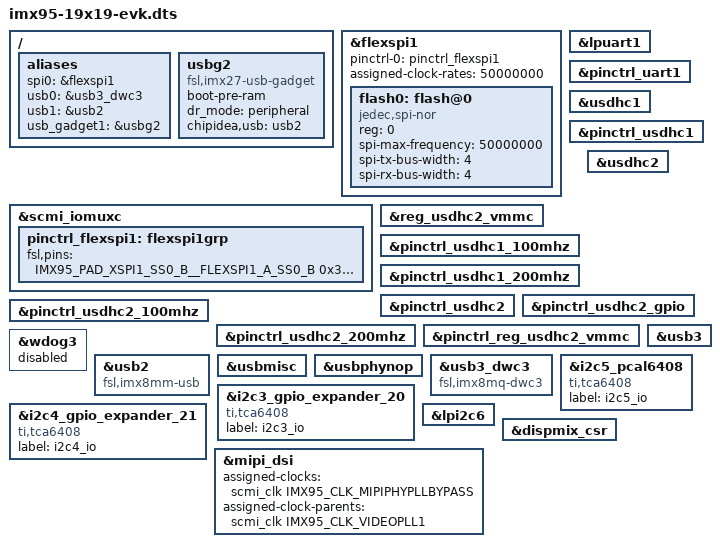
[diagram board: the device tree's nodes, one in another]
// SPDX-License-Identifier: (GPL-2.0+ OR MIT)
/*
 * Copyright 2023-2024 NXP
 */

#include "../dts/upstream/src/arm64/freescale/imx95-19x19-evk.dts"
#include "imx95-u-boot.dtsi"
#include "imx95-19x19-evk-local.dtsi"

&flexspi1 {
	/delete-node/ flash@0;
};

/delete-node/ &pinctrl_flexspi1;
/delete-node/ &pinctrl_flexspi1_reset;

/ {
	aliases {
		spi0 = &flexspi1;
		usb0 = &usb3_dwc3;
		usb1 = &usb2;
		usb_gadget1 = &usbg2;
	};

	usbg2: usbg2 {
		boot-pre-ram;
		compatible = "fsl,imx27-usb-gadget";
		dr_mode = "peripheral";
		chipidea,usb = <&usb2>;
		status = "okay";
	};
};

&flexspi1 {
	bootph-pre-ram;
	pinctrl-names = "default";
	pinctrl-0 = <&pinctrl_flexspi1>;
	assigned-clock-rates = <50000000>; // 50 MHz
	status = "okay";

	flash0: flash@0 {
		bootph-pre-ram;
		compatible = "jedec,spi-nor";
		reg = <0>;
		#address-cells = <1>;
		#size-cells = <1>;
		spi-max-frequency = <50000000>; // 50 MHz
		spi-tx-bus-width = <4>;
		spi-rx-bus-width = <4>;
	};
};

&scmi_iomuxc {
	pinctrl-names = "default";

	pinctrl_flexspi1: flexspi1grp {
		bootph-pre-ram;
		fsl,pins = <
			IMX95_PAD_XSPI1_SS0_B__FLEXSPI1_A_SS0_B		0x3fe
			IMX95_PAD_XSPI1_SCLK__FLEXSPI1_A_SCLK		0x3fe
			IMX95_PAD_XSPI1_DATA0__FLEXSPI1_A_DATA_BIT0	0x3fe
			IMX95_PAD_XSPI1_DATA1__FLEXSPI1_A_DATA_BIT1	0x3fe
			IMX95_PAD_XSPI1_DATA2__FLEXSPI1_A_DATA_BIT2	0x3fe
			IMX95_PAD_XSPI1_DATA3__FLEXSPI1_A_DATA_BIT3	0x3fe
		>;
	};
};

&lpuart1 {
	bootph-pre-ram;
};

&pinctrl_uart1 {
	bootph-pre-ram;
};

&reg_usdhc2_vmmc {
	bootph-pre-ram;
};

&usdhc1 {
	bootph-pre-ram;
};

&pinctrl_usdhc1 {
	bootph-pre-ram;
};

&pinctrl_usdhc1_100mhz {
	bootph-pre-ram;
};

&pinctrl_usdhc1_200mhz {
	bootph-pre-ram;
};

&usdhc2 {
	bootph-pre-ram;
};

&pinctrl_usdhc2 {
	bootph-pre-ram;
};

&pinctrl_usdhc2_100mhz {
	bootph-pre-ram;
};

&pinctrl_usdhc2_200mhz {
	bootph-pre-ram;
};

&pinctrl_usdhc2_gpio {
	bootph-pre-ram;
};

&pinctrl_reg_usdhc2_vmmc {
	bootph-pre-ram;
};

&wdog3 {
	status = "disabled";
};

&usb2 {
	bootph-pre-ram;
	compatible = "fsl,imx8mm-usb", "fsl,imx7d-usb";
	/delete-property/ power-domains;
};

&usbmisc {
	bootph-pre-ram;
};

&usbphynop {
	bootph-pre-ram;
};

&usb3 {
	/delete-property/ power-domains;
};

&usb3_dwc3 {
	compatible = "fsl,imx8mq-dwc3", "snps,dwc3";
};

&i2c3_gpio_expander_20 {
	compatible = "ti,tca6408";
	label = "i2c3_io";
};

&i2c4_gpio_expander_21 {
	compatible = "ti,tca6408";
	label = "i2c4_io";
};

&i2c5_pcal6408 {
	compatible = "ti,tca6408";
	label = "i2c5_io";
};

/delete-node/ &i2c6_pcal6416;

&lpi2c6 {
	/delete-node/ gpio@21;	
};

&dispmix_csr {
	/delete-property/ assigned-clocks;
	/delete-property/ assigned-clock-rates;
	/delete-property/ assigned-clock-parents;
};

&mipi_dsi {
	assigned-clocks = <&scmi_clk IMX95_CLK_MIPIPHYPLLBYPASS>;
	assigned-clock-parents = <&scmi_clk IMX95_CLK_VIDEOPLL1>;
};
